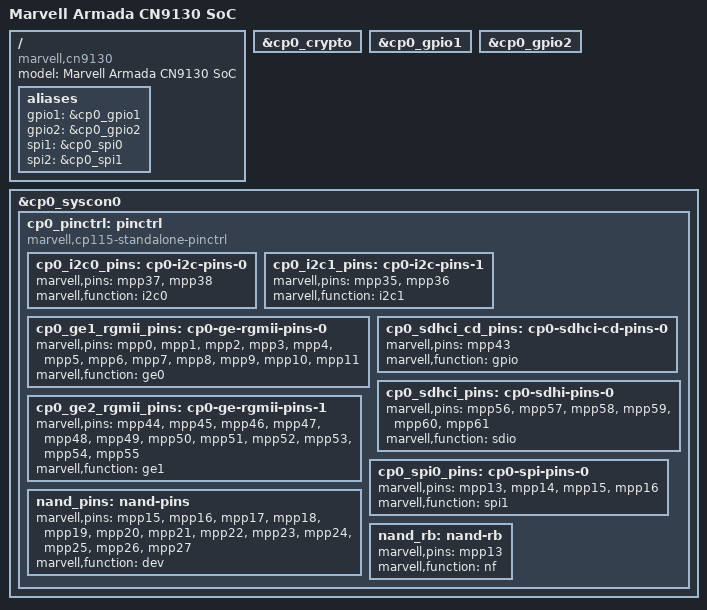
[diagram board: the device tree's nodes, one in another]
// SPDX-License-Identifier: (GPL-2.0+ OR MIT)
/*
 * Copyright (C) 2019 Marvell International Ltd.
 *
 * Device tree for the CN9130 SoC.
 */

#include "armada-ap807-quad.dtsi"
// {
//    aliases {
  //      gpio1 = &cp0_gpio1;
    //    gpio2 = &cp0_gpio2;
  //      spi1 = &cp0_spi0;
 //       spi2 = &cp0_spi1;
//    };
//};

/*
 * Instantiate the internal CP115
 */

#define CP11X_NAME		cp0
#define CP11X_BASE		f2000000
#define CP11X_PCIEx_MEM_BASE(iface) ((iface == 0) ? 0xc0000000 : \
						    0xe0000000 + ((iface - 1) * 0x1000000))
#define CP11X_PCIEx_MEM_SIZE(iface) ((iface == 0) ? 0x1ff00000 : 0xf00000)
#define CP11X_PCIE0_BASE	f2600000
#define CP11X_PCIE1_BASE	f2620000
#define CP11X_PCIE2_BASE	f2640000

#include "armada-cp115.dtsi"

#undef CP11X_NAME
#undef CP11X_BASE
#undef CP11X_PCIEx_MEM_BASE
#undef CP11X_PCIEx_MEM_SIZE
#undef CP11X_PCIE0_BASE
#undef CP11X_PCIE1_BASE
#undef CP11X_PCIE2_BASE

/ {
   model = "Marvell Armada CN9130 SoC";
   compatible = "marvell,cn9130", "marvell,armada-cp11x", "marvell,armada-cp115", "marvell,armada-ap807-quad",
          "marvell,armada-ap807";
    aliases {
        gpio1 = &cp0_gpio1;
        gpio2 = &cp0_gpio2;
        spi1 = &cp0_spi0;
        spi2 = &cp0_spi1;
    };

};

&cp0_crypto {
    status = "okay";
};

&cp0_gpio1 {
    status = "okay";
};

&cp0_gpio2 {
    status = "okay";
};

&cp0_syscon0 {
    cp0_pinctrl: pinctrl {
        compatible = "marvell,cp115-standalone-pinctrl";

        cp0_i2c0_pins: cp0-i2c-pins-0 {
            marvell,pins = "mpp37", "mpp38";
            marvell,function = "i2c0";
        };
        cp0_i2c1_pins: cp0-i2c-pins-1 {
            marvell,pins = "mpp35", "mpp36";
            marvell,function = "i2c1";
        };
        cp0_ge1_rgmii_pins: cp0-ge-rgmii-pins-0 {
            marvell,pins = "mpp0", "mpp1", "mpp2",
                       "mpp3", "mpp4", "mpp5",
                       "mpp6", "mpp7", "mpp8",
                       "mpp9", "mpp10", "mpp11";
            marvell,function = "ge0";
        };
        cp0_ge2_rgmii_pins: cp0-ge-rgmii-pins-1 {
            marvell,pins = "mpp44", "mpp45", "mpp46",
                       "mpp47", "mpp48", "mpp49",
                       "mpp50", "mpp51", "mpp52",
                       "mpp53", "mpp54", "mpp55";
            marvell,function = "ge1";
        };
        cp0_sdhci_cd_pins: cp0-sdhci-cd-pins-0 {
            marvell,pins = "mpp43";
            marvell,function = "gpio";
        };
        cp0_sdhci_pins: cp0-sdhi-pins-0 {
            marvell,pins = "mpp56", "mpp57", "mpp58",
                       "mpp59", "mpp60", "mpp61";
            marvell,function = "sdio";
        };
        cp0_spi0_pins: cp0-spi-pins-0 {
            marvell,pins = "mpp13", "mpp14", "mpp15", "mpp16";
            marvell,function = "spi1";
        };
        nand_pins: nand-pins {
            marvell,pins =
            "mpp15", "mpp16", "mpp17", "mpp18", "mpp19",
            "mpp20", "mpp21", "mpp22", "mpp23", "mpp24",
            "mpp25", "mpp26", "mpp27";
            marvell,function = "dev";
        };
        nand_rb: nand-rb {
            marvell,pins = "mpp13";
            marvell,function = "nf";
        };
    };
};


